# STM32MP25_CM33 register map
File version: 1.3
CPU: CM33 r0p1, little endian, MPU, FPU, vendor SysTick, 8 interrupt priority bits
Registers are 32-bit, read-write, reset 0x0 unless marked. A register's access mark holds for its fields unless they carry their own. Offsets are from the block's base; [hi:lo] are bit positions; lines under a group give offsets from that group.

## GICC — GICC address block description
Base 0x4AC20000
Same registers: GICC_S 0x5AC20000
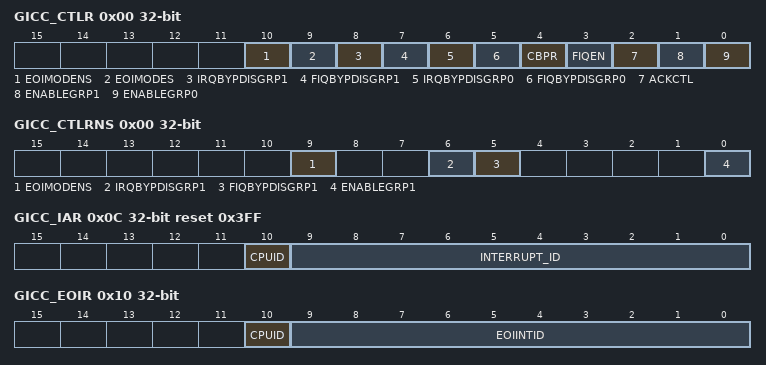
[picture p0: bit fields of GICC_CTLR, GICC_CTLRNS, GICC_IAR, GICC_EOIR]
0x00 GICC_CTLR — GICC control register
  [10] EOIMODENS — Alias of EOIMODENS from the non-secure copy of this register.
  [9] EOIMODES — EOI mode for secure accesses
  [8] IRQBYPDISGRP1 — Alias of IRQBYPDISGRP1 from the non-secure copy of this register.
  [7] FIQBYPDISGRP1 — Alias of FIQBYPDISGRP1 from the non-secure copy of this register.
  [6] IRQBYPDISGRP0 — IRQ bypass disable for group 0 interrupts
  [5] FIQBYPDISGRP0 — FIQ bypass disable for group 0 interrupts
  [4] CBPR — BPR control
  [3] FIQEN — FIQ enable for group 0 interrupts
  [2] ACKCTL — Acknowledge control
  [1] ENABLEGRP1 — Enable group 1 interrupts
  [0] ENABLEGRP0 — Enable group 0 interrupts
0x00 GICC_CTLRNS (alternate view of GICC_CTLR) — GICC control non-secure access register
  [9] EOIMODENS — EOI mode for non- secure accesses
  [6] IRQBYPDISGRP1 — IRQ bypass for group 1 interrupts
  [5] FIQBYPDISGRP1 — FIQ bypass disable for group 1 interrupts
  [0] ENABLEGRP1 — Enable group1 interrupts
0x04 GICC_PMR — GICC input priority mask register
  [7:3] PRIORITY — Priority mask level for the CPU interface
0x08 GICC_BPR reset 0x2 — GICC binary point register
  [2:0] BINARY_POINT — This bit field value controls how the 8-bit interrupt priority field is split into a group priority field. It is used to determine interrupt preemption and a subpriority field. Minimum value is 2.
0x08 GICC_BPRNS reset 0x3 (alternate view of GICC_BPR) — GICC binary point non-secure access register
  [2:0] BINARY_POINT — This bit field value controls how the 8-bit interrupt priority field is split into a group priority field. It is used to determine interrupt preemption and a subpriority field. Minimum value is 3.
0x0C GICC_IAR ro reset 0x3FF — GICC interrupt acknowledge register
  [10] CPUID — CPU requesting the interrupt
  [9:0] INTERRUPT_ID
0x10 GICC_EOIR wo reset not defined — GICC end of interrupt register
  [10] CPUID — On a multiprocessor implementation, if the write refers to an SGI, this bit contains the CPUID value from the corresponding GICC_IAR access.
  [9:0] EOIINTID — Interrupt ID value from the corresponding GICC_IAR access
0x14 GICC_RPR ro reset 0xFF — GICC running priority register
  [7:3] PRIORITY — Current running priority on the CPU interface
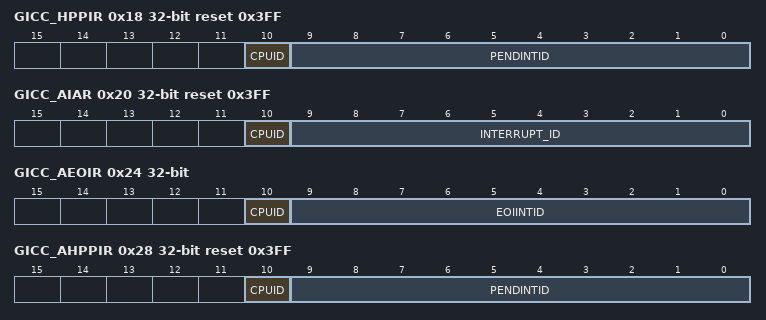
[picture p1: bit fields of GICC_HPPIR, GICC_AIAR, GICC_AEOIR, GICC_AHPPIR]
0x18 GICC_HPPIR ro reset 0x3FF — GICC highest priority pending interrupt register
  [10] CPUID — On a multiprocessor implementation, if the PENDINTID bit field returns the ID of an SGI, this bit contains the CPUID value for this interrupt. This identifies the processor that generated the interrupt.
  [9:0] PENDINTID — Interrupt ID of the highest-priority pending interrupt
0x1C GICC_ABPR reset 0x3 — GICC aliased binary point register
  [2:0] BINARY_POINT — The value of this bit field controls how the 8-bit interrupt priority field is split into a group priority field. It is used to determine interrupt preemption, and a subpriority field.
0x20 GICC_AIAR ro reset 0x3FF — GICC aliased interrupt acknowledge register
  [10] CPUID — For SGIs in a multiprocessor implementation, this bit identifies the processor that requested the interrupt. It returns the number of the CPU interface that made the request.
  [9:0] INTERRUPT_ID
0x24 GICC_AEOIR wo reset not defined — GICC aliased end of interrupt register
  [10] CPUID — On a multiprocessor implementation, when processing an SGI, this bit must contain the CPUID value from the corresponding GICC_AIAR, or non-secure GICC_IAR, access.
  [9:0] EOIINTID — This bit field contains the interrupt ID value from the corresponding GICC_AIAR, or non-secure GICC_IAR, access.
0x28 GICC_AHPPIR ro reset 0x3FF — GICC aliased highest priority pending interrupt register
  [10] CPUID — On a multiprocessor implementation, if the PENDINTID bit field returns the ID of an SGI, this bit contains the CPUID value for that interrupt. This identifies the processor that generated the interrupt.
  [9:0] PENDINTID — Interrupt ID of the highest-priority pending interrupt
0xD0 GICC_APR0 — GICC active priority register
  [31:0] APR0 — Active priority
0xE0 GICC_NSAPR0 — GICC non-secure active priority register
  [31:0] NSAPR0 — Non-secure active priority
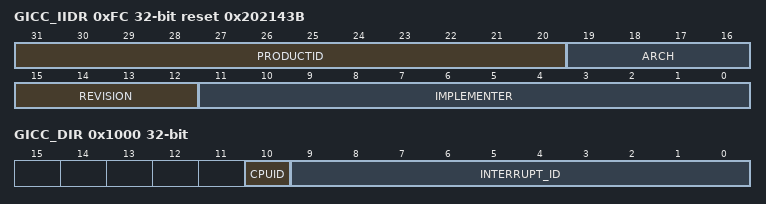
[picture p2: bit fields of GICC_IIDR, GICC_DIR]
0xFC GICC_IIDR ro reset 0x202143B — GICC interface identification register
  [31:20] PRODUCTID
  [19:16] ARCH — GIC architecture version
  [15:12] REVISION — revision number for the CPU interface
  [11:0] IMPLEMENTER — GIC implementer (0x43B Arm implementation)
0x1000 GICC_DIR wo reset not defined — GICC deactivate interrupt register
  [10] CPUID — For an SGI in a multiprocessor implementation, this bit identifies the processor that requested the interrupt
  [9:0] INTERRUPT_ID
